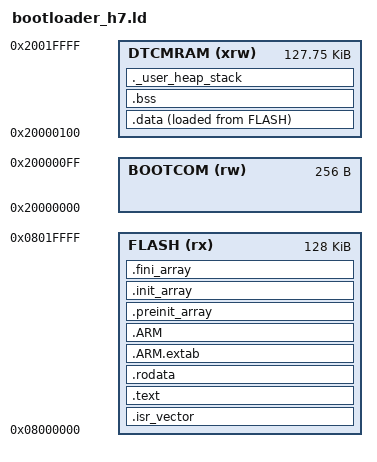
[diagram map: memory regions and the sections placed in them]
/*
 * BR_bootloader linker script -- STM32H7 (MicroNodePlus H723, CoreNode H743).
 *
 * Layout (single script serves both boards -- the bootloader region is the
 * same regardless of total chip flash size):
 *   FLASH:   0x08000000, 128 KB  -- the first H7 flash sector. The app is
 *                                   placed at 0x08020000 (sector 1) so erasing
 *                                   the app never touches the bootloader.
 *   BOOTCOM: 0x20000000, 256 B   -- IPC region shared with the application.
 *                                   Layout matches the L4 bootloader's BOOTCOM
 *                                   (struct app_bootloader_comms, magic
 *                                   0xc544ad9a) so the same DroneCAN app code
 *                                   works on both MCU families.
 *   DTCMRAM: 0x20000100, 128 KB - 256 B  -- bootloader's .bss/.data/stack.
 *                                   Fast, CPU-only-accessible -- ideal since
 *                                   the bootloader doesn't need DMA-friendly
 *                                   RAM. Leaves the larger D1/D2/D3 SRAMs
 *                                   completely untouched for the app.
 */

ENTRY(Reset_Handler)

_estack = ORIGIN(DTCMRAM) + LENGTH(DTCMRAM);

_Min_Heap_Size  = 0x200;
_Min_Stack_Size = 0x400;

MEMORY
{
  FLASH   (rx)  : ORIGIN = 0x08000000, LENGTH = 128K
  BOOTCOM (rw)  : ORIGIN = 0x20000000, LENGTH = 0x100
  DTCMRAM (xrw) : ORIGIN = 0x20000100, LENGTH = 128K - 0x100
}

SECTIONS
{
  .isr_vector :
  {
    . = ALIGN(4);
    KEEP(*(.isr_vector))
    . = ALIGN(4);
  } >FLASH

  .text :
  {
    . = ALIGN(4);
    *(.text)
    *(.text*)
    *(.glue_7)
    *(.glue_7t)
    *(.eh_frame)

    KEEP (*(.init))
    KEEP (*(.fini))

    . = ALIGN(4);
    _etext = .;
  } >FLASH

  .rodata :
  {
    . = ALIGN(4);
    *(.rodata)
    *(.rodata*)
    . = ALIGN(4);
  } >FLASH

  .ARM.extab (READONLY) :
  {
    . = ALIGN(4);
    *(.ARM.extab* .gnu.linkonce.armextab.*)
    . = ALIGN(4);
  } >FLASH

  .ARM (READONLY) :
  {
    . = ALIGN(4);
    __exidx_start = .;
    *(.ARM.exidx*)
    __exidx_end = .;
    . = ALIGN(4);
  } >FLASH

  .preinit_array (READONLY) :
  {
    . = ALIGN(4);
    PROVIDE_HIDDEN (__preinit_array_start = .);
    KEEP (*(.preinit_array*))
    PROVIDE_HIDDEN (__preinit_array_end = .);
    . = ALIGN(4);
  } >FLASH

  .init_array (READONLY) :
  {
    . = ALIGN(4);
    PROVIDE_HIDDEN (__init_array_start = .);
    KEEP (*(SORT(.init_array.*)))
    KEEP (*(.init_array*))
    PROVIDE_HIDDEN (__init_array_end = .);
    . = ALIGN(4);
  } >FLASH

  .fini_array (READONLY) :
  {
    . = ALIGN(4);
    PROVIDE_HIDDEN (__fini_array_start = .);
    KEEP (*(SORT(.fini_array.*)))
    KEEP (*(.fini_array*))
    PROVIDE_HIDDEN (__fini_array_end = .);
    . = ALIGN(4);
  } >FLASH

  _sidata = LOADADDR(.data);

  .data :
  {
    . = ALIGN(4);
    _sdata = .;
    *(.data)
    *(.data*)
    *(.RamFunc)
    *(.RamFunc*)
    . = ALIGN(4);
    _edata = .;
  } >DTCMRAM AT> FLASH

  . = ALIGN(4);
  .bss :
  {
    _sbss = .;
    __bss_start__ = _sbss;
    *(.bss)
    *(.bss*)
    *(COMMON)
    . = ALIGN(4);
    _ebss = .;
    __bss_end__ = _ebss;
  } >DTCMRAM

  ._user_heap_stack :
  {
    . = ALIGN(8);
    PROVIDE ( end = . );
    PROVIDE ( _end = . );
    . = . + _Min_Heap_Size;
    . = . + _Min_Stack_Size;
    . = ALIGN(8);
  } >DTCMRAM

  /DISCARD/ :
  {
    libc.a ( * )
    libm.a ( * )
    libgcc.a ( * )
  }

  .ARM.attributes 0 : { *(.ARM.attributes) }
}
